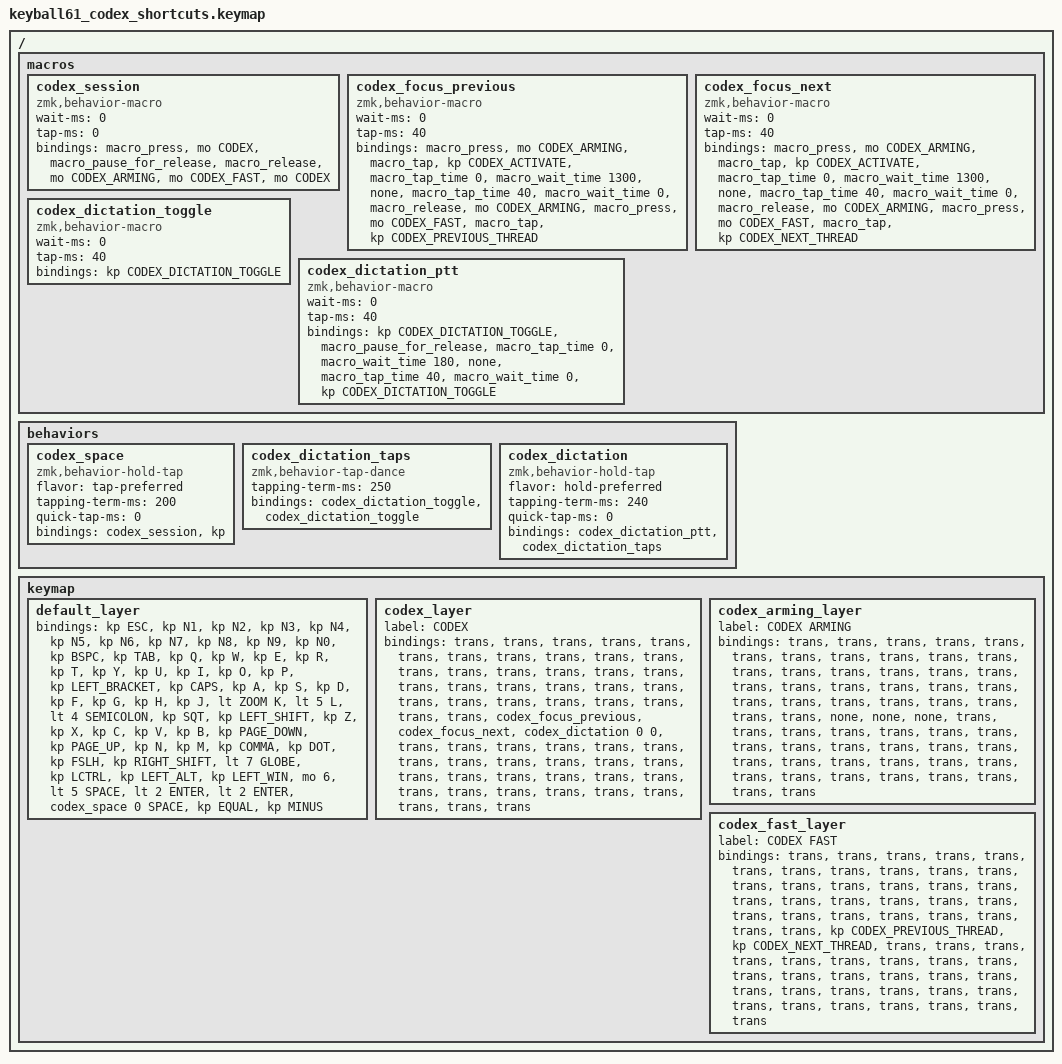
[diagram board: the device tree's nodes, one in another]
/* SPDX-License-Identifier: MIT */

/*
 * Stock-HID Codex shortcuts layered on top of the verified daily keymap.
 * This target intentionally adds no vendor HID interface or Codex emulation
 * shield: every host action below is an ordinary keyboard shortcut.
 */
#include "keyball61.keymap"

#define CODEX         9
#define CODEX_ARMING 10
#define CODEX_FAST   11

#define CODEX_ACTIVATE          LC(LA(LG(F)))
#define CODEX_PREVIOUS_THREAD   LG(LS(LEFT_BRACKET))
#define CODEX_NEXT_THREAD       LG(LS(RIGHT_BRACKET))
#define CODEX_DICTATION_TOGGLE  LC(LA(LS(F19)))

/ {
    macros {
        /*
         * Keep CODEX active only while right Space is held.  The two transient
         * layers are also released here so every new Space hold starts from a
         * known state, including when Space is released during the focus wait.
         */
        codex_session: codex_session {
            compatible = "zmk,behavior-macro";
            #binding-cells = <0>;
            wait-ms = <0>;
            tap-ms = <0>;
            bindings
                = <&macro_press &mo CODEX>
                , <&macro_pause_for_release>
                , <&macro_release &mo CODEX_ARMING &mo CODEX_FAST &mo CODEX>
                ;
        };

        /*
         * The first J press starts an upward CODEX session. ARMING absorbs
         * extra navigation/dictation presses while macOS brings Codex forward;
         * FAST then makes later J/K presses direct HID events instead of
         * queuing another 1300 ms macro.
         * The zero-time &none tap creates the true pre-action delay because a
         * macro wait otherwise applies after its preceding action.
         */
        codex_focus_previous: codex_focus_previous {
            compatible = "zmk,behavior-macro";
            #binding-cells = <0>;
            wait-ms = <0>;
            tap-ms = <40>;
            bindings
                = <&macro_press &mo CODEX_ARMING>
                , <&macro_tap &kp CODEX_ACTIVATE>
                , <&macro_tap_time 0>
                , <&macro_wait_time 1300>
                , <&none>
                , <&macro_tap_time 40>
                , <&macro_wait_time 0>
                , <&macro_release &mo CODEX_ARMING>
                , <&macro_press &mo CODEX_FAST>
                , <&macro_tap &kp CODEX_PREVIOUS_THREAD>
                ;
        };

        /* The first K press is the same session setup, moving downward. */
        codex_focus_next: codex_focus_next {
            compatible = "zmk,behavior-macro";
            #binding-cells = <0>;
            wait-ms = <0>;
            tap-ms = <40>;
            bindings
                = <&macro_press &mo CODEX_ARMING>
                , <&macro_tap &kp CODEX_ACTIVATE>
                , <&macro_tap_time 0>
                , <&macro_wait_time 1300>
                , <&none>
                , <&macro_tap_time 40>
                , <&macro_wait_time 0>
                , <&macro_release &mo CODEX_ARMING>
                , <&macro_press &mo CODEX_FAST>
                , <&macro_tap &kp CODEX_NEXT_THREAD>
                ;
        };

        /* One ordinary HID pulse for ChatGPT's global Toggle Dictation key. */
        codex_dictation_toggle: codex_dictation_toggle {
            compatible = "zmk,behavior-macro";
            #binding-cells = <0>;
            wait-ms = <0>;
            tap-ms = <40>;
            bindings = <&kp CODEX_DICTATION_TOGGLE>;
        };

        /*
         * Hold-to-dictate is implemented by toggling on when the hold resolves,
         * pausing until physical release, then toggling off.  The inert queue
         * item enforces a 180 ms post-release delay before the stop pulse.
         */
        codex_dictation_ptt: codex_dictation_ptt {
            compatible = "zmk,behavior-macro";
            #binding-cells = <0>;
            wait-ms = <0>;
            tap-ms = <40>;
            bindings
                = <&kp CODEX_DICTATION_TOGGLE>
                , <&macro_pause_for_release>
                , <&macro_tap_time 0>
                , <&macro_wait_time 180>
                , <&none>
                , <&macro_tap_time 40>
                , <&macro_wait_time 0>
                , <&kp CODEX_DICTATION_TOGGLE>
                ;
        };
    };

    behaviors {
        /*
         * Unlike ZMK's shared &lt behavior, this layer-tap has no quick-tap
         * window.  A Space hold therefore always reaches CODEX, even when it
         * immediately follows an ordinary Space tap while typing.
         */
        codex_space: codex_space {
            compatible = "zmk,behavior-hold-tap";
            #binding-cells = <2>;
            flavor = "tap-preferred";
            tapping-term-ms = <200>;
            quick-tap-ms = <0>;
            bindings = <&codex_session>, <&kp>;
        };

        /* A single or double tap deliberately produces one toggle pulse. */
        codex_dictation_taps: codex_dictation_taps {
            compatible = "zmk,behavior-tap-dance";
            #binding-cells = <0>;
            tapping-term-ms = <250>;
            bindings = <&codex_dictation_toggle>, <&codex_dictation_toggle>;
        };

        /*
         * Hold L for momentary dictation; tap/double-tap L for latched
         * dictation. Parameters are unused but required by hold-tap's ABI.
         */
        codex_dictation: codex_dictation {
            compatible = "zmk,behavior-hold-tap";
            #binding-cells = <2>;
            flavor = "hold-preferred";
            tapping-term-ms = <240>;
            quick-tap-ms = <0>;
            bindings = <&codex_dictation_ptt>, <&codex_dictation_taps>;
        };
    };

    keymap {
        default_layer {
            bindings = <
&kp ESC         &kp N1     &kp N2        &kp N3        &kp N4  &kp N5                                   &kp N6       &kp N7  &kp N8     &kp N9   &kp N0           &kp BSPC
&kp TAB         &kp Q      &kp W         &kp E         &kp R   &kp T                                    &kp Y        &kp U   &kp I      &kp O    &kp P            &kp LEFT_BRACKET
&kp CAPS        &kp A      &kp S         &kp D         &kp F   &kp G                                    &kp H        &kp J   &lt ZOOM K  &lt 5 L  &lt 4 SEMICOLON  &kp SQT
&kp LEFT_SHIFT  &kp Z      &kp X         &kp C         &kp V   &kp B        &kp PAGE_DOWN  &kp PAGE_UP  &kp N        &kp M   &kp COMMA  &kp DOT  &kp FSLH         &kp RIGHT_SHIFT
&lt 7 GLOBE     &kp LCTRL  &kp LEFT_ALT  &kp LEFT_WIN  &mo 6   &lt 5 SPACE  &lt 2 ENTER    &lt 2 ENTER  &codex_space 0 SPACE                     &kp EQUAL        &kp MINUS
            >;
        };

        codex_layer {
            label = "CODEX";
            bindings = <
&trans  &trans  &trans  &trans  &trans  &trans                  &trans  &trans                 &trans                    &trans  &trans  &trans
&trans  &trans  &trans  &trans  &trans  &trans                  &trans  &trans                 &trans                    &trans  &trans  &trans
&trans  &trans  &trans  &trans  &trans  &trans                  &trans  &codex_focus_previous  &codex_focus_next  &codex_dictation 0 0  &trans  &trans
&trans  &trans  &trans  &trans  &trans  &trans  &trans  &trans  &trans  &trans                 &trans                    &trans  &trans  &trans
&trans  &trans  &trans  &trans  &trans  &trans  &trans  &trans  &trans                                                   &trans  &trans
            >;
        };

        codex_arming_layer {
            label = "CODEX ARMING";
            bindings = <
&trans  &trans  &trans  &trans  &trans  &trans                  &trans  &trans  &trans  &trans  &trans  &trans
&trans  &trans  &trans  &trans  &trans  &trans                  &trans  &trans  &trans  &trans  &trans  &trans
&trans  &trans  &trans  &trans  &trans  &trans                  &trans  &none   &none   &none   &trans  &trans
&trans  &trans  &trans  &trans  &trans  &trans  &trans  &trans  &trans  &trans  &trans  &trans  &trans  &trans
&trans  &trans  &trans  &trans  &trans  &trans  &trans  &trans  &trans                          &trans  &trans
            >;
        };

        codex_fast_layer {
            label = "CODEX FAST";
            bindings = <
&trans  &trans  &trans  &trans  &trans  &trans                  &trans  &trans                       &trans  &trans  &trans  &trans
&trans  &trans  &trans  &trans  &trans  &trans                  &trans  &trans                       &trans  &trans  &trans  &trans
&trans  &trans  &trans  &trans  &trans  &trans                  &trans  &kp CODEX_PREVIOUS_THREAD  &kp CODEX_NEXT_THREAD  &trans  &trans  &trans
&trans  &trans  &trans  &trans  &trans  &trans  &trans  &trans  &trans  &trans                       &trans  &trans  &trans  &trans
&trans  &trans  &trans  &trans  &trans  &trans  &trans  &trans  &trans                                &trans  &trans
            >;
        };
    };
};
